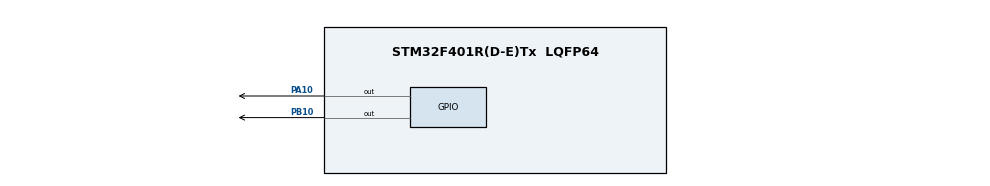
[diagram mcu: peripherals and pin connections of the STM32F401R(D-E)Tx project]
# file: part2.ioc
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Mcu.Family=STM32F4
Mcu.Name=STM32F401R(D-E)Tx
Mcu.Package=LQFP64
NVIC.PriorityGroup=NVIC_PRIORITYGROUP_4
PA10.Signal=GPIO_Output
PB10.Signal=GPIO_Output
ProjectManager.HeapSize=0x200
ProjectManager.StackSize=0x400
ProjectManager.TargetToolchain=STM32CubeIDE
RCC.48MHZClocksFreq_Value=84000000
RCC.AHBFreq_Value=84000000
RCC.APB1CLKDivider=RCC_HCLK_DIV2
RCC.APB1Freq_Value=42000000
RCC.APB1TimFreq_Value=84000000
RCC.APB2Freq_Value=84000000
RCC.APB2TimFreq_Value=84000000
RCC.CortexFreq_Value=84000000
RCC.HCLKFreq_Value=84000000
RCC.HSE_VALUE=25000000
RCC.HSI_VALUE=16000000
RCC.LSE_VALUE=32768
RCC.PLLN=336
RCC.PLLP=RCC_PLLP_DIV4
RCC.SYSCLKFreq_VALUE=84000000
RCC.SYSCLKSource=RCC_SYSCLKSOURCE_PLLCLK
RCC.VCOOutputFreq_Value=336000000
TIM3.Channel-Output\ Compare1\ No\ Output=TIM_CHANNEL_1
TIM3.Channel-Output\ Compare2\ No\ Output=TIM_CHANNEL_2
TIM3.Period=65535
VP_TIM3_VS_ClockSourceINT.Mode=Internal
VP_TIM3_VS_no_output1.Mode=Output Compare1 No Output
VP_TIM3_VS_no_output2.Mode=Output Compare2 No Output
board=custom

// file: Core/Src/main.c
/* USER CODE BEGIN Header */
/**
 ******************************************************************************
 * @file           : main.c
 * @brief          : Main program body
 ******************************************************************************
 * @attention
 *
 * Copyright (c) 2025 STMicroelectronics.
 * All rights reserved.
 *
 * This software is licensed under terms that can be found in the LICENSE file
 * in the root directory of this software component.
 * If no LICENSE file comes with this software, it is provided AS-IS.
 *
 ******************************************************************************
 */
/* USER CODE END Header */
#include "main.h"

/* USER CODE BEGIN PD */
#define HALF_PERIOD1 16800 // 2.5 kHz
#define HALF_PERIOD2 3360 // 12.5 kHz
/* USER CODE END PD */

void SystemClock_Config(void);
static void MX_GPIO_Init(void);
static void MX_TIM3_Init(void);

int main(void) {

	/* MCU Configuration--------------------------------------------------------*/

	/* Reset of all peripherals, Initializes the Flash interface and the Systick. */
	LL_APB2_GRP1_EnableClock(LL_APB2_GRP1_PERIPH_SYSCFG);
	LL_APB1_GRP1_EnableClock(LL_APB1_GRP1_PERIPH_PWR);

	/* System interrupt init*/
	NVIC_SetPriorityGrouping(NVIC_PRIORITYGROUP_4);

	/* SysTick_IRQn interrupt configuration */
	NVIC_SetPriority(SysTick_IRQn,
			NVIC_EncodePriority(NVIC_GetPriorityGrouping(), 15, 0));

	/* Configure the system clock */
	SystemClock_Config();

	/* Initialize all configured peripherals */
	MX_GPIO_Init();
	MX_TIM3_Init();
	/* USER CODE BEGIN 2 */
	SysTick_Config(SystemCoreClock / 1000);
	LL_TIM_WriteReg(TIM3, CR1, LL_TIM_ReadReg(TIM3,CR1) | 0x1); // enable counter
	LL_TIM_WriteReg(TIM3, CNT, 0); // initialize counter
	/* USER CODE END 2 */

	/* Infinite loop */
	while (1) {
		/* USER CODE BEGIN 3 */
		int StatR = LL_TIM_ReadReg(TIM3, SR);
		int cc1if = (StatR >> 1) & 0x1; //Ch1
		int cc2if = (StatR >> 2) & 0x1; //Ch2
		if (cc1if == 1) {
			LL_TIM_WriteReg(TIM3, SR, LL_TIM_ReadReg(TIM3,SR) & ~(0b010)); // clear flag
			LL_GPIO_WriteReg(GPIOA, ODR,
					LL_GPIO_ReadReg(GPIOA, ODR) ^ (1U << 10)); // toggle output
			LL_TIM_WriteReg(TIM3, CCR1,
					LL_TIM_ReadReg(TIM3, CCR1) + HALF_PERIOD1); //TC1 += HALF_PERIOD1
		}
		if (cc2if == 1) {
			LL_TIM_WriteReg(TIM3, SR, LL_TIM_ReadReg(TIM3,SR) & ~(0b100)); // clear flag
			LL_GPIO_WriteReg(GPIOB, ODR,
					LL_GPIO_ReadReg(GPIOB, ODR) ^ (1U << 10)); // toggle output
			LL_TIM_WriteReg(TIM3, CCR2,
					LL_TIM_ReadReg(TIM3, CCR2) + HALF_PERIOD2); //TC2 += HALF_PERIOD2
		}

	}
	/* USER CODE END 3 */
}

void SystemClock_Config(void) {
	LL_FLASH_SetLatency(LL_FLASH_LATENCY_2);
	while (LL_FLASH_GetLatency() != LL_FLASH_LATENCY_2) {
	}
	LL_PWR_SetRegulVoltageScaling(LL_PWR_REGU_VOLTAGE_SCALE2);
	LL_RCC_HSI_SetCalibTrimming(16);
	LL_RCC_HSI_Enable();

	/* Wait till HSI is ready */
	while (LL_RCC_HSI_IsReady() != 1) {

	}
	LL_RCC_PLL_ConfigDomain_SYS(LL_RCC_PLLSOURCE_HSI, LL_RCC_PLLM_DIV_16, 336,
			LL_RCC_PLLP_DIV_4);
	LL_RCC_PLL_Enable();

	/* Wait till PLL is ready */
	while (LL_RCC_PLL_IsReady() != 1) {

	}
	while (LL_PWR_IsActiveFlag_VOS() == 0) {
	}
	LL_RCC_SetAHBPrescaler(LL_RCC_SYSCLK_DIV_1);
	LL_RCC_SetAPB1Prescaler(LL_RCC_APB1_DIV_2);
	LL_RCC_SetAPB2Prescaler(LL_RCC_APB2_DIV_1);
	LL_RCC_SetSysClkSource(LL_RCC_SYS_CLKSOURCE_PLL);

	/* Wait till System clock is ready */
	while (LL_RCC_GetSysClkSource() != LL_RCC_SYS_CLKSOURCE_STATUS_PLL) {

	}
	LL_Init1msTick(84000000);
	LL_SetSystemCoreClock(84000000);
	LL_RCC_SetTIMPrescaler(LL_RCC_TIM_PRESCALER_TWICE);
}

static void MX_TIM3_Init(void) {

	LL_TIM_InitTypeDef TIM_InitStruct = { 0 };
	LL_TIM_OC_InitTypeDef TIM_OC_InitStruct = { 0 };

	/* Peripheral clock enable */
	LL_APB1_GRP1_EnableClock(LL_APB1_GRP1_PERIPH_TIM3);

	TIM_InitStruct.Prescaler = 0;
	TIM_InitStruct.CounterMode = LL_TIM_COUNTERMODE_UP;
	TIM_InitStruct.Autoreload = 65535;
	TIM_InitStruct.ClockDivision = LL_TIM_CLOCKDIVISION_DIV1;
	LL_TIM_Init(TIM3, &TIM_InitStruct);
	LL_TIM_DisableARRPreload(TIM3);
	LL_TIM_SetClockSource(TIM3, LL_TIM_CLOCKSOURCE_INTERNAL);
	TIM_OC_InitStruct.OCMode = LL_TIM_OCMODE_FROZEN;
	TIM_OC_InitStruct.OCState = LL_TIM_OCSTATE_ENABLE;
	TIM_OC_InitStruct.OCNState = LL_TIM_OCSTATE_DISABLE;
	TIM_OC_InitStruct.CompareValue = 0;
	TIM_OC_InitStruct.OCPolarity = LL_TIM_OCPOLARITY_HIGH;
	LL_TIM_OC_Init(TIM3, LL_TIM_CHANNEL_CH1, &TIM_OC_InitStruct);
	LL_TIM_OC_DisableFast(TIM3, LL_TIM_CHANNEL_CH1);
	LL_TIM_OC_Init(TIM3, LL_TIM_CHANNEL_CH2, &TIM_OC_InitStruct);
	LL_TIM_OC_DisableFast(TIM3, LL_TIM_CHANNEL_CH2);
	LL_TIM_SetTriggerOutput(TIM3, LL_TIM_TRGO_RESET);
	LL_TIM_DisableMasterSlaveMode(TIM3);

}

static void MX_GPIO_Init(void) {
	LL_GPIO_InitTypeDef GPIO_InitStruct = { 0 };

	/* GPIO Ports Clock Enable */
	LL_AHB1_GRP1_EnableClock(LL_AHB1_GRP1_PERIPH_GPIOB);
	LL_AHB1_GRP1_EnableClock(LL_AHB1_GRP1_PERIPH_GPIOA);

	/**/
	LL_GPIO_ResetOutputPin(GPIOB, LL_GPIO_PIN_10);

	/**/
	LL_GPIO_ResetOutputPin(GPIOA, LL_GPIO_PIN_10);

	/**/
	GPIO_InitStruct.Pin = LL_GPIO_PIN_10;
	GPIO_InitStruct.Mode = LL_GPIO_MODE_OUTPUT;
	GPIO_InitStruct.Speed = LL_GPIO_SPEED_FREQ_LOW;
	GPIO_InitStruct.OutputType = LL_GPIO_OUTPUT_PUSHPULL;
	GPIO_InitStruct.Pull = LL_GPIO_PULL_NO;
	LL_GPIO_Init(GPIOB, &GPIO_InitStruct);

	/**/
	GPIO_InitStruct.Pin = LL_GPIO_PIN_10;
	GPIO_InitStruct.Mode = LL_GPIO_MODE_OUTPUT;
	GPIO_InitStruct.Speed = LL_GPIO_SPEED_FREQ_LOW;
	GPIO_InitStruct.OutputType = LL_GPIO_OUTPUT_PUSHPULL;
	GPIO_InitStruct.Pull = LL_GPIO_PULL_NO;
	LL_GPIO_Init(GPIOA, &GPIO_InitStruct);

}

void Error_Handler(void) {
	__disable_irq();
	while (1) {
	}
}
